# STM32L496xx register map
File version: 1.0
Registers are 32-bit, read-write, reset 0x0 unless marked. A register's access mark holds for its fields unless they carry their own. Offsets are from the block's base; [hi:lo] are bit positions; {n}, {i} and the like mark numbered series; 'fields as' and 'values as' point back to an identical list.

## DCMI
Base 0x50050000
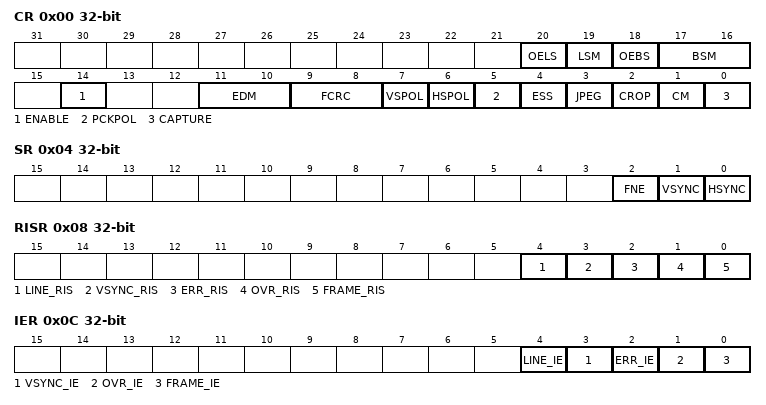
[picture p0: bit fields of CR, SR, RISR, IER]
0x00 CR — DCMI control register
  [20] OELS — DCMI Odd/Even Line Select (Line Select Start)
  [19] LSM — DCMI Line Select mode
  [18] OEBS — DCMI Odd/Even Byte Select (Byte Select Start)
  [17:16] BSM — DCMI Byte Select mode BSM[1:0]
  [14] ENABLE — DCMI DCMI enable
  [11:10] EDM — DCMI Extended data mode EDM[1:0]
  [9:8] FCRC — DCMI Frame capture rate control FCRC[1:0]
  [7] VSPOL — DCMI Vertical synchronization polarity
  [6] HSPOL — DCMI Horizontal synchronization polarity
  [5] PCKPOL — DCMI Pixel clock polarity
  [4] ESS — DCMI Embedded synchronization select
  [3] JPEG — DCMI JPEG format
  [2] CROP — DCMI Crop feature
  [1] CM — DCMI Capture mode
  [0] CAPTURE — DCMI Capture enable
0x04 SR — DCMI status register
  [2] FNE — DCMI FIFO not empty
  [1] VSYNC
  [0] HSYNC
0x08 RISR — DCMI raw interrupt status register
  [4] LINE_RIS — DCMI Line raw interrupt status
  [3] VSYNC_RIS — DCMI VSYNC raw interrupt status
  [2] ERR_RIS — DCMI Synchronization error raw interrupt status
  [1] OVR_RIS — DCMI Overrun raw interrupt status
  [0] FRAME_RIS — DCMI Capture complete raw interrupt status
0x0C IER — DCMI interrupt enable register
  [4] LINE_IE — DCMI Line interrupt enable
  [3] VSYNC_IE — DCMI VSYNC interrupt enable
  [2] ERR_IE — DCMI Synchronization error interrupt enable
  [1] OVR_IE — DCMI Overrun interrupt enable
  [0] FRAME_IE — DCMI Capture complete interrupt enable
0x0C IER_ALT (alternate view of IER) — DCMI interrupt enable register
  [4:0] INT_IE
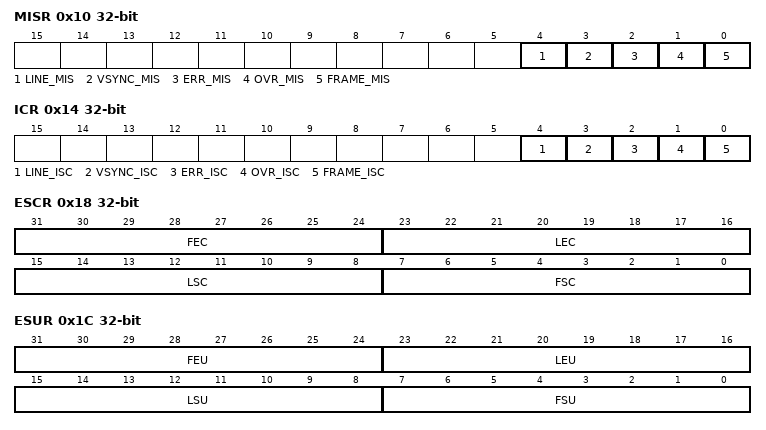
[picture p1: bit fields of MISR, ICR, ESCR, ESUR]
0x10 MISR — DCMI masked interrupt status register
  [4] LINE_MIS — DCMI Line masked interrupt status
  [3] VSYNC_MIS — DCMI VSYNC masked interrupt status
  [2] ERR_MIS — DCMI Synchronization error masked interrupt status
  [1] OVR_MIS — DCMI Overrun masked interrupt status
  [0] FRAME_MIS — DCMI Capture complete masked interrupt status
0x14 ICR — DCMI interrupt clear register
  [4] LINE_ISC — DCMI line interrupt status clear
  [3] VSYNC_ISC — DCMI Vertical synch interrupt status clear
  [2] ERR_ISC — DCMI Synchronization error interrupt status clear
  [1] OVR_ISC — DCMI Overrun interrupt status clear
  [0] FRAME_ISC — DCMI Capture complete interrupt status clear
0x18 ESCR — DCMI embedded synchronization code register
  [31:24] FEC — DCMI Frame end delimiter code FEC[7:0]
  [23:16] LEC — DCMI Line end delimiter code LEC[7:0]
  [15:8] LSC — DCMI Line start delimiter code LSC[7:0]
  [7:0] FSC — DCMI Frame start delimiter code FSC[7:0]
0x1C ESUR — DCMI embedded synchronization unmask register
  [31:24] FEU — DCMI Frame end delimiter unmask FEU[7:0]
  [23:16] LEU — DCMI Line end delimiter unmask LEU[7:0]
  [15:8] LSU — DCMI Line start delimiter unmask LSU[7:0]
  [7:0] FSU — DCMI Frame start delimiter unmask FSU[7:0]
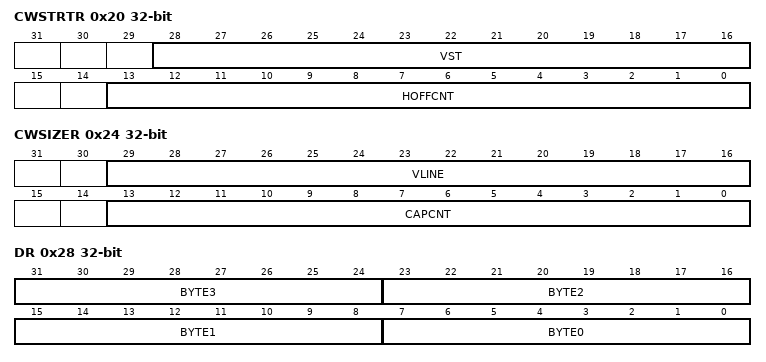
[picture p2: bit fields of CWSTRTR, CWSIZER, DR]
0x20 CWSTRTR — DCMI crop window start
  [28:16] VST — DCMI Vertical start line count VST[12:0]
  [13:0] HOFFCNT — DCMI Horizontal offset count HOFFCNT[13:0]
0x24 CWSIZER — DCMI crop window size
  [29:16] VLINE — DCMI Vertical line count VLINE[13:0]
  [13:0] CAPCNT — DCMI Capture count CAPCNT[13:0]
0x28 DR — DCMI data register
  [8n+7:8n] BYTE{n} (n=0..3) — DCMI Data byte {n} Byte{n}[7:0]

## RNG
Base 0x50060800
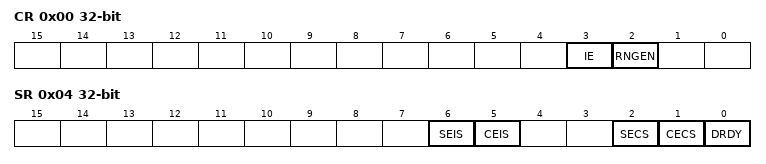
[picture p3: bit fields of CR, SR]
0x00 CR — RNG control register
  [3] IE, [2] RNGEN
0x04 SR — RNG status register
  [6] SEIS, [5] CEIS, [2] SECS, [1] CECS, [0] DRDY
0x08 DR — RNG data register

## FMC_Bank1_R — Flexible Memory Controller
Base 0xA0000000
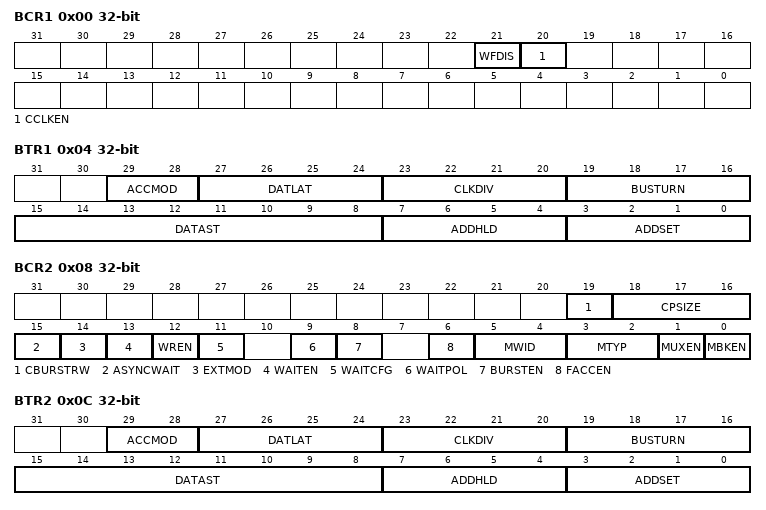
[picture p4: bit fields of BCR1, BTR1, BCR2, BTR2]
0x00 BCR1 — NOR/PSRAM chip-select control register(BCR) and chip-select timing register(BTR)
  [21] WFDIS — Write FIFO Disable
  [20] CCLKEN — Continuous clock enable
0x04 BTR1 — NOR/PSRAM chip-select control register(BCR) and chip-select timing register(BTR)
  [29:28] ACCMOD — ACCMOD[1:0] bits (Access mode)
  [27:24] DATLAT — DATLAT[3:0] bits (Data latency)
  [23:20] CLKDIV — CLKDIV[3:0] bits (Clock divide ratio)
  [19:16] BUSTURN — BUSTURN[3:0] bits (Bus turnaround phase duration)
  [15:8] DATAST — DATAST [3:0] bits (Data-phase duration)
  [7:4] ADDHLD — ADDHLD[3:0] bits (Address-hold phase duration)
  [3:0] ADDSET — ADDSET[3:0] bits (Address setup phase duration)
0x08 BCR2 — NOR/PSRAM chip-select control register(BCR) and chip-select timing register(BTR)
  [19] CBURSTRW — Write burst enable
  [18:16] CPSIZE — CRAM page size
  [15] ASYNCWAIT — Asynchronous wait
  [14] EXTMOD — Extended mode enable
  [13] WAITEN — Wait enable bit
  [12] WREN — Write enable bit
  [11] WAITCFG — Wait timing configuration
  [9] WAITPOL — Wait signal polarity bit
  [8] BURSTEN — Burst enable bit
  [6] FACCEN — Flash access enable
  [5:4] MWID — MWID[1:0] bits (Memory data bus width)
  [3:2] MTYP — MTYP[1:0] bits (Memory type)
  [1] MUXEN — Address/data multiplexing enable bit
  [0] MBKEN — Memory bank enable bit
0x0C BTR2 — NOR/PSRAM chip-select control register(BCR) and chip-select timing register(BTR)
  fields as BTR1
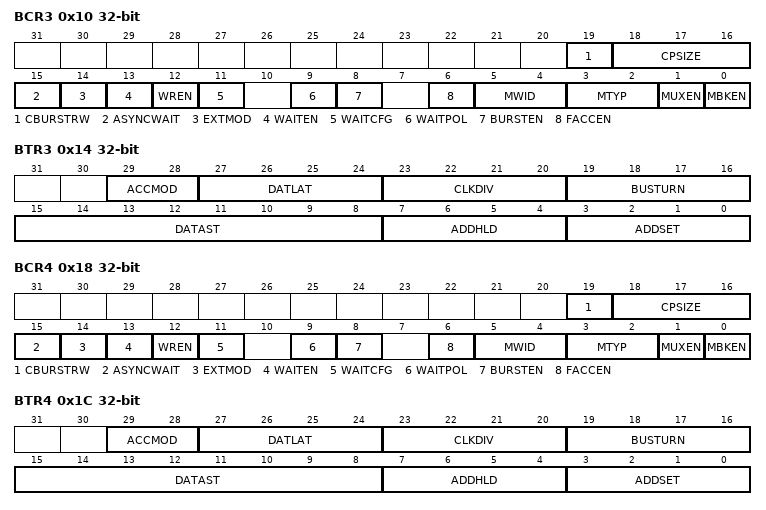
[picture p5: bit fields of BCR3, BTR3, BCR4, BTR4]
0x10 BCR3 — NOR/PSRAM chip-select control register(BCR) and chip-select timing register(BTR)
  fields as BCR2
0x14 BTR3 — NOR/PSRAM chip-select control register(BCR) and chip-select timing register(BTR)
  fields as BTR1
0x18 BCR4 — NOR/PSRAM chip-select control register(BCR) and chip-select timing register(BTR)
  fields as BCR2
0x1C BTR4 — NOR/PSRAM chip-select control register(BCR) and chip-select timing register(BTR)
  fields as BTR1
